# HC32F558 register map
File version: 1.0
CPU: CM4 r0p1, little endian, MPU, FPU, 4 interrupt priority bits
Registers are 32-bit, read-write, reset 0x0 unless marked. A register's access mark holds for its fields unless they carry their own. Offsets are from the block's base; [hi:lo] are bit positions; {n}, {i} and the like mark numbered series.

## ERMU
Base 0x40048800
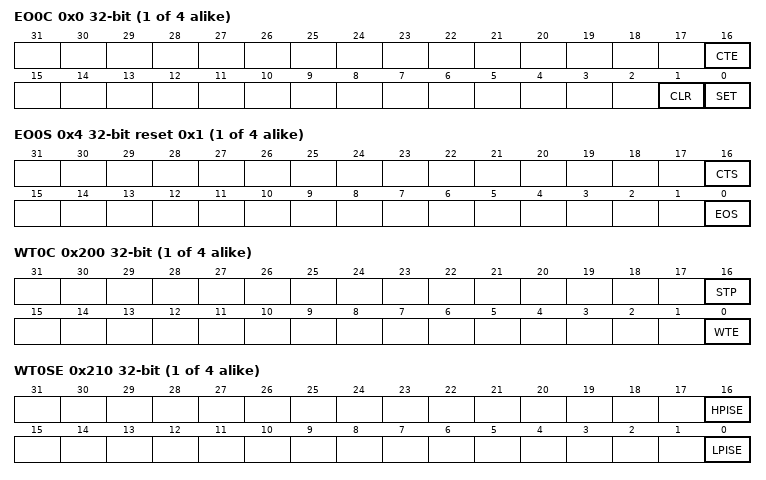
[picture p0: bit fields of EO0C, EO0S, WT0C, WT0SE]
{0x0+0x80*i} EO{i}C (i=0..3)
  [16] CTE, [1] CLR wo, [0] SET wo
{0x4+0x80*i} EO{i}S ro reset 0x1 (i=0..3)
  [16] CTS, [0] EOS
{0x8+0x80*i} EO{i}CTCNT ro (i=0..3)
  [15:0] CNT
{0xC+0x80*i} EO{i}CTCMP (i=0..3)
  [15:0] CMP
{0x10+0x80*i} EO{i}TTC (i=0..3)
  [0] TTE
{0x14+0x80*i} EO{i}TTCNT ro (i=0..3)
  [15:0] CNT
{0x18+0x80*i} EO{i}TTCMP (i=0..3)
  [15:0] CMP
{0x40+0x80*i} EO{i}OM0 (i=0..3)
  [31:0] OM
{0x44+0x80*i} EO{i}OM1 (i=0..3)
  [31:0] OM
{0x200+0x20*i} WT{i}C (i=0..3)
  [16] STP wo, [0] WTE
{0x204+0x20*i} WT{i}S ro (i=0..3)
  [0] WTS
{0x208+0x20*i} WT{i}CNT ro (i=0..3)
  [15:0] CNT
{0x20C+0x20*i} WT{i}CMP (i=0..3)
  [15:0] CMP
{0x210+0x20*i} WT{i}SE (i=0..3)
  [16] HPISE, [0] LPISE
0x300 ESS0 ro
  [31:0] ESS
0x304 ESS1 ro
  [31:0] ESS
0x340 ESSC0 wo
  [31:0] ESSC
0x344 ESSC1 wo
  [31:0] ESSC
0x380 PET0 wo
  [31:0] PET
0x384 PET1 wo
  [31:0] PET
0x3C0 RE0
  [31:0] RE
0x3C4 RE1
  [31:0] RE
0x400 LPIE0
  [31:0] LPIE
0x404 LPIE1
  [31:0] LPIE
0x500 HPIE0
  [31:0] HPIE
0x504 HPIE1
  [31:0] HPIE
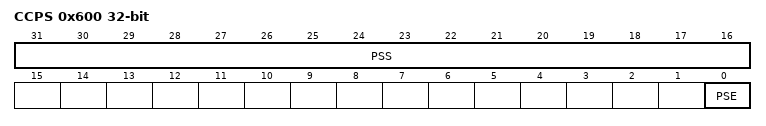
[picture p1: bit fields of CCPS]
0x600 CCPS
  [31:16] PSS, [0] PSE

## FCM1 — desc FCM
Base 0x40048400
Same registers: FCM2 0x40048440, FCM3 0x40048480, FCM4 0x400484C0
0x00 LVR
  [15:0] LVR
0x04 UVR
  [15:0] UVR
0x08 CNTR ro
  [15:0] CNTR
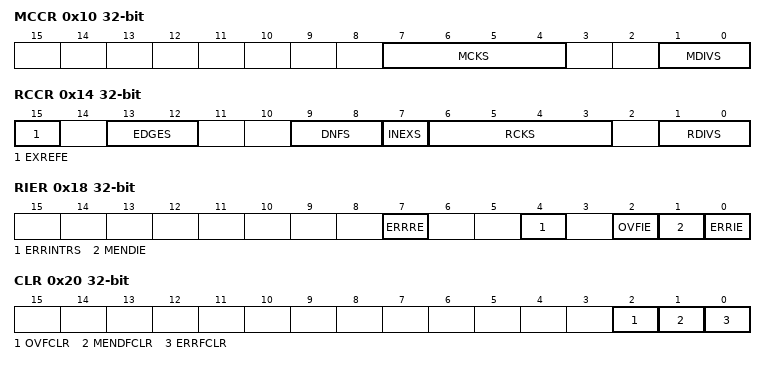
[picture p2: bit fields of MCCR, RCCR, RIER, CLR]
0x10 MCCR
  [7:4] MCKS, [1:0] MDIVS
0x14 RCCR
  [15] EXREFE, [13:12] EDGES, [9:8] DNFS, [7] INEXS, [6:3] RCKS, [1:0] RDIVS
0x18 RIER
  [7] ERRRE, [4] ERRINTRS, [2] OVFIE, [1] MENDIE, [0] ERRIE
0x20 CLR wo
  [2] OVFCLR, [1] MENDFCLR, [0] ERRFCLR

## FCM_COM
Base 0x40048400; alternate view of FCM1
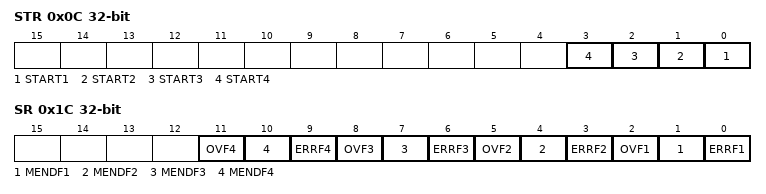
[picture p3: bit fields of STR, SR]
0x0C STR
  [n-1] START{n} (n=1..4)
0x1C SR ro
  [3n-1] OVF{n} (n=1..4), [3n-2] MENDF{n} (n=1..4), [3n-3] ERRF{n} (n=1..4)

## FMAC
Base 0x40058000
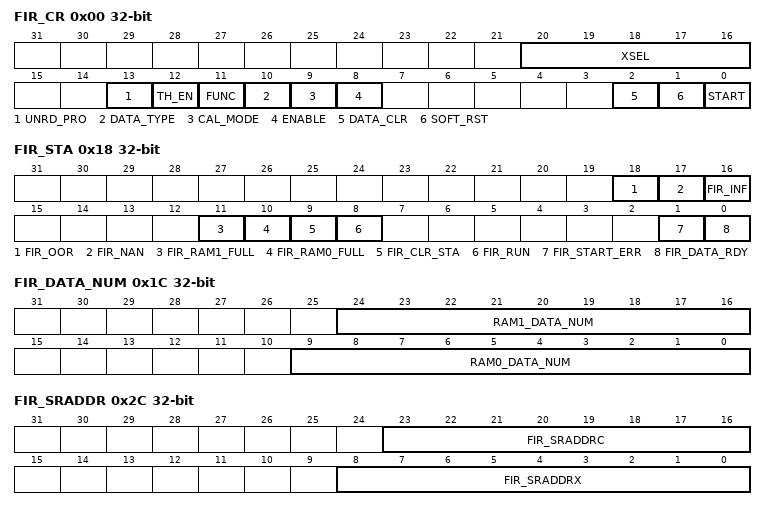
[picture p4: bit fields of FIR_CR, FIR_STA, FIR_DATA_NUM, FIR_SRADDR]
0x00 FIR_CR
  [20:16] XSEL, [13] UNRD_PRO, [12] TH_EN, [11] FUNC, [10] DATA_TYPE, [9] CAL_MODE, [8] ENABLE, [2] DATA_CLR, [1] SOFT_RST, [0] START
0x04 FIR_XWDATA
0x08 FIR_CWDATA
0x0C FIR_PARM reset 0x3FF
  [7:0] COEF_NUM
0x10 FIR_YRDATA ro
0x14 FIR_INT_CR
  [0] FIR_DONE_EN
0x18 FIR_STA
  [18] FIR_OOR, [17] FIR_NAN, [16] FIR_INF, [11] FIR_RAM1_FULL ro, [10] FIR_RAM0_FULL ro, [9] FIR_CLR_STA ro, [8] FIR_RUN ro, [1] FIR_START_ERR, [0] FIR_DATA_RDY
0x1C FIR_DATA_NUM ro
  [24:16] RAM1_DATA_NUM, [9:0] RAM0_DATA_NUM
0x20 FIR_AVG_COEF
0x24 FIR_YMAX
0x28 FIR_YMIN
0x2C FIR_SRADDR
  [23:16] FIR_SRADDRC, [8:0] FIR_SRADDRX
0x30 FIR_SRDATAX ro
0x34 FIR_SRDATAC ro
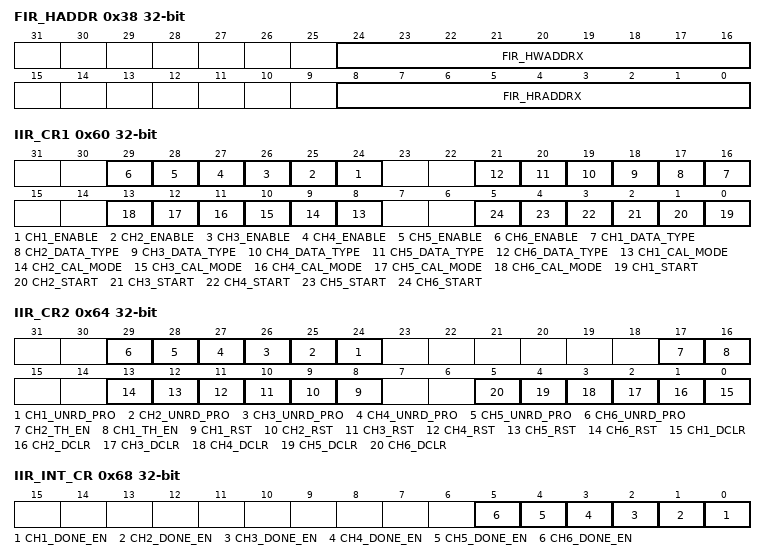
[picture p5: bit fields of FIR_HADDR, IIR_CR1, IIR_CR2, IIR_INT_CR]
0x38 FIR_HADDR ro
  [24:16] FIR_HWADDRX, [8:0] FIR_HRADDRX
0x60 IIR_CR1
  [n+23] CH{n}_ENABLE (n=1..6), [n+15] CH{n}_DATA_TYPE (n=1..6), [n+7] CH{n}_CAL_MODE (n=1..6), [n-1] CH{n}_START (n=1..6)
0x64 IIR_CR2
  [n+23] CH{n}_UNRD_PRO (n=1..6), [17] CH2_TH_EN, [16] CH1_TH_EN, [n+7] CH{n}_RST (n=1..6), [n-1] CH{n}_DCLR (n=1..6)
0x68 IIR_INT_CR
  [n-1] CH{n}_DONE_EN (n=1..6)
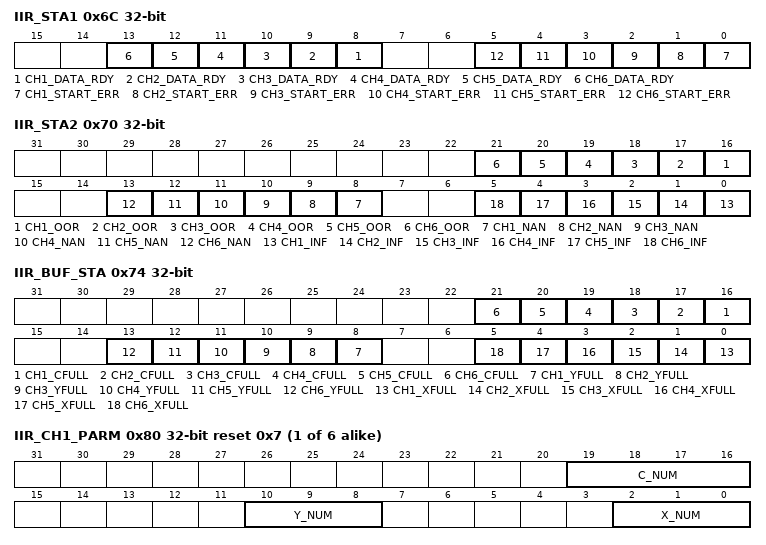
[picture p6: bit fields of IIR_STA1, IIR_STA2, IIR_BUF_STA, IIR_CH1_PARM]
0x6C IIR_STA1
  [n+7] CH{n}_DATA_RDY (n=1..6), [n-1] CH{n}_START_ERR (n=1..6)
0x70 IIR_STA2
  [n+15] CH{n}_OOR (n=1..6), [n+7] CH{n}_NAN (n=1..6), [n-1] CH{n}_INF (n=1..6)
0x74 IIR_BUF_STA
  [n+15] CH{n}_CFULL (n=1..6), [n+7] CH{n}_YFULL (n=1..6), [n-1] CH{n}_XFULL (n=1..6)
{0x7C+4i} IIR_CH{i}_PARM reset 0x7 (i=1..6)
  [19:16] C_NUM, [10:8] Y_NUM, [2:0] X_NUM
{0x9C+4i} IIR_YRDATA{i} ro (i=1..6)
{0xBC+4i} IIR_XWDATA{i} wo (i=1..6)
{0xDC+4i} IIR_CWDATA{i} wo (i=1..6)
{0xFC+4i} IIR_YWDATA{i} wo (i=1..6)
0x120 IIR_YMAX1
0x124 IIR_YMAX2
0x140 IIR_YMIN1
0x144 IIR_YMIN2
{0x15C+4i} IIR_DATA_CR{i} (i=1..6)
  [4:0] XSEL
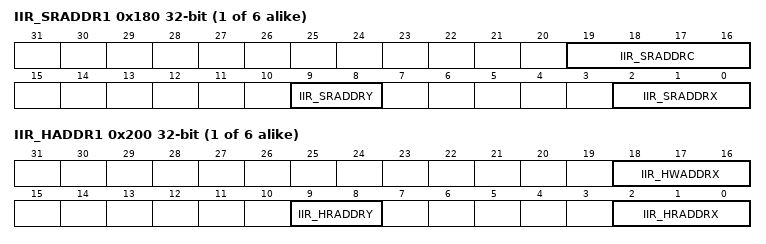
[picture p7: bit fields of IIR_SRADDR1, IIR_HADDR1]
{0x17C+4i} IIR_SRADDR{i} (i=1..6)
  [19:16] IIR_SRADDRC, [9:8] IIR_SRADDRY, [2:0] IIR_SRADDRX
{0x19C+4i} IIR_SRDATAX{i} ro (i=1..6)
{0x1BC+4i} IIR_SRDATAC{i} ro (i=1..6)
{0x1DC+4i} IIR_SRDATAY{i} ro (i=1..5)
0x1F5 IIR_SRDATAY6 ro
{0x1FC+4i} IIR_HADDR{i} ro (i=1..6)
  [18:16] IIR_HWADDRX, [9:8] IIR_HRADDRY, [2:0] IIR_HRADDRX
